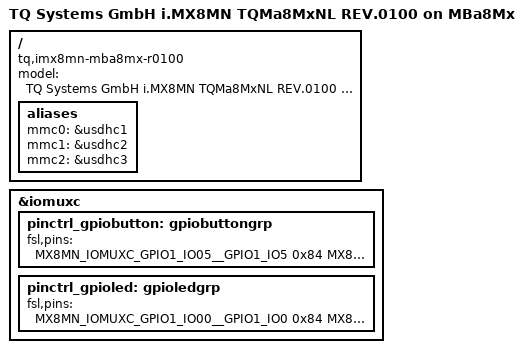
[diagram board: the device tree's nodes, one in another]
// SPDX-License-Identifier: GPL-2.0+
/*
 * Copyright 2021 TQ-Systems GmbH
 */

/dts-v1/;

#include "fsl-imx8mn-tqma8mxnl-r0100.dtsi"
#include "fsl-imx8mn-mba8mx.dtsi"

/delete-node/ &pinctrl_gpiobutton;
/delete-node/ &pinctrl_gpioled;

/ {
	model = "TQ Systems GmbH i.MX8MN TQMa8MxNL REV.0100 on MBa8Mx";
	compatible = "tq,imx8mn-mba8mx-r0100", "tq,imx8mn-tqma8mxnl-r0100", "fsl,imx8mn";

	aliases {
		mmc0 = &usdhc1;
		mmc1 = &usdhc2;
		mmc2 = &usdhc3;
	};

};

&iomuxc {
	pinctrl_gpiobutton: gpiobuttongrp {
		fsl,pins = <
			MX8MN_IOMUXC_GPIO1_IO05__GPIO1_IO5	0x84
			MX8MN_IOMUXC_GPIO1_IO07__GPIO1_IO7	0x84
			MX8MN_IOMUXC_NAND_WE_B__GPIO3_IO17	0x84
		>;
	};

	pinctrl_gpioled: gpioledgrp {
		fsl,pins = <
			MX8MN_IOMUXC_GPIO1_IO00__GPIO1_IO0	0x84
			MX8MN_IOMUXC_GPIO1_IO08__GPIO1_IO8	0x84
			MX8MN_IOMUXC_NAND_READY_B__GPIO3_IO16	0x84
		>;
	};
};
